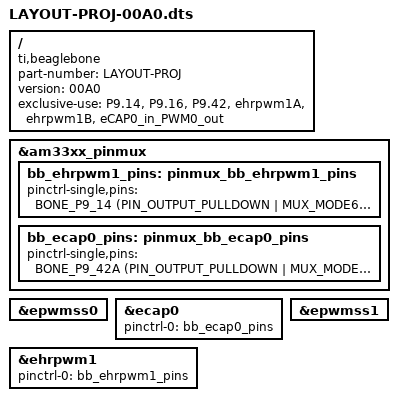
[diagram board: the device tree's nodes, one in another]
/dts-v1/;
/plugin/;

#include <dt-bindings/board/am335x-bbw-bbb-base.h>
#include <dt-bindings/gpio/gpio.h>
#include <dt-bindings/pinctrl/am33xx.h>


 /{
	compatible = "ti,beaglebone", "ti,beaglebone-black", "ti,beaglebone-green";

	/* identification */
	part-number = "LAYOUT-PROJ";
	version = "00A0";

	/* state the resources this cape uses */
	exclusive-use =

				/* - PIN - */

		/* --- PWM --- */
		"P9.14", 			/* PWM CHIP1/PWM0  EHRPWM1A */
		"P9.16",			/* PWM 			   EHRPWM1B */
		"P9.42",	/* pwm: eCAP0_in_PWM0_out */

			  /* - HARDWARE ADRESS - */

		/* --- PWM --- */
		"ehrpwm1A",
		"ehrpwm1B",
		"eCAP0_in_PWM0_out";



	fragment@0 
	{
		target = <&am33xx_pinmux>;
		__overlay__ 
		{

			bb_ehrpwm1_pins: pinmux_bb_ehrpwm1_pins
			{
				pinctrl-single,pins = <
					BONE_P9_14 (PIN_OUTPUT_PULLDOWN | MUX_MODE6) /* P9_14 (ZCZ ball U14) | MODE 6 */
					BONE_P9_16 (PIN_OUTPUT_PULLDOWN | MUX_MODE6) /* P9_16 (ZCZ ball T14) | MODE 6 */
				>;
			};

			bb_ecap0_pins: pinmux_bb_ecap0_pins
			{
				pinctrl-single,pins = <
					BONE_P9_42A (PIN_OUTPUT_PULLDOWN | MUX_MODE0) /* P9_42 (ZCZ ball C18) | MODE 0 */
				>;
			};

			
		};
	};

	fragment@1 {
		target = <&epwmss0>;
		__overlay__ {
			status = "okay";
		};
	};

	fragment@2 {
		target = <&ecap0>;
		__overlay__ {
			pinctrl-names = "default";
			pinctrl-0 = <&bb_ecap0_pins>;
			status = "okay";
		};
	};

    fragment@3
     {
            target = <&epwmss1>;
            __overlay__
            {
            status = "okay";
            };
    };


	fragment@4
	{
		target = <&ehrpwm1>;
		__overlay__
		{
			pinctrl-names = "default";
			pinctrl-0 = <&bb_ehrpwm1_pins>;
			status = "okay";
		};
	};


};
